AUTOSAR XML (schema 4-2-2)
package /ComponentTypes
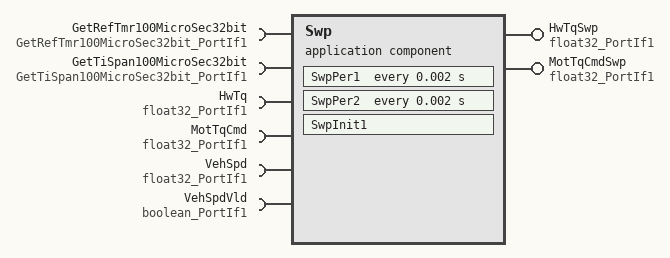
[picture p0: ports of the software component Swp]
  application sw component type Swp
    provide port HwTqSwp: nonqueued-sender-com-spec{data-element=Val, init-value=0}, provided-interface=float32_PortIf1
    provide port MotTqCmdSwp: nonqueued-sender-com-spec{data-element=Val, init-value=0}, provided-interface=float32_PortIf1
    6 x require port:
      GetRefTmr100MicroSec32bit: client-com-spec=Oper, required-interface=GetRefTmr100MicroSec32bit_PortIf1
      GetTiSpan100MicroSec32bit: client-com-spec=Oper, required-interface=GetTiSpan100MicroSec32bit_PortIf1
      HwTq: nonqueued-receiver-com-spec{data-element=Val, filter=data-filter-type=ALWAYS, init-value=0}, required-interface=float32_PortIf1
      MotTqCmd: nonqueued-receiver-com-spec{data-element=Val, filter=data-filter-type=ALWAYS, init-value=0}, required-interface=float32_PortIf1
      VehSpd: nonqueued-receiver-com-spec{data-element=Val, filter=data-filter-type=ALWAYS, init-value=0}, required-interface=float32_PortIf1
      VehSpdVld: nonqueued-receiver-com-spec{data-element=Logl, filter=data-filter-type=ALWAYS, init-value=0}, required-interface=boolean_PortIf1
    behavior Swp_InternalBehavior
      init event Swp_InitEvent: start-on-event=SwpInit1
      timing event TMT_SwpPer1: start-on-event=SwpPer1, period=0.002
      timing event TMT_SwpPer2: start-on-event=SwpPer2, period=0.002
      runnable SwpInit1
      runnable SwpPer1: minimum-start-interval=0.002
        data-receive-point-by-arguments:
          access REC_HwTq_Val: accessed-variable=HwTq.Val
          access REC_VehSpd_Val: accessed-variable=VehSpd.Val
          access REC_VehSpdVld_Logl: accessed-variable=VehSpdVld.Logl
        data-send-points:
          access SEND_HwTqSwp_Val: accessed-variable=HwTqSwp.Val
        sync call SC_GetRefTmr100MicroSec32bit_Oper: operation=GetRefTmr100MicroSec32bit.Oper, timeout=0
        sync call SC_GetTiSpan100MicroSec32bit_Oper: operation=GetTiSpan100MicroSec32bit.Oper, timeout=0
      runnable SwpPer2: minimum-start-interval=0.002
        data-receive-point-by-arguments:
          access REC_MotTqCmd_Val: accessed-variable=MotTqCmd.Val
        data-send-points:
          access SEND_MotTqSwp_Val: accessed-variable=MotTqCmdSwp.Val
  swc implementation Swp_Implementation: behavior=Swp_InternalBehavior
    code-descriptors:
      code Default: artifact-descriptors=autosar-engineering-object={short-label=Default, category=SWSRC}
